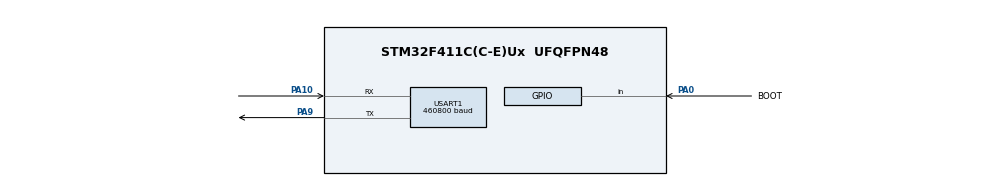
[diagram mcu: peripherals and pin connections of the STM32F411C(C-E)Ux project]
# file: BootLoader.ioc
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Dma.Request0=USART1_RX
Dma.USART1_RX.0.Direction=DMA_PERIPH_TO_MEMORY
Dma.USART1_RX.0.FIFOMode=DMA_FIFOMODE_DISABLE
Dma.USART1_RX.0.Instance=DMA2_Stream2
Dma.USART1_RX.0.MemDataAlignment=DMA_MDATAALIGN_BYTE
Dma.USART1_RX.0.MemInc=DMA_MINC_ENABLE
Dma.USART1_RX.0.Mode=DMA_CIRCULAR
Dma.USART1_RX.0.PeriphDataAlignment=DMA_PDATAALIGN_BYTE
Dma.USART1_RX.0.PeriphInc=DMA_PINC_DISABLE
Dma.USART1_RX.0.Priority=DMA_PRIORITY_HIGH
Mcu.Family=STM32F4
Mcu.Name=STM32F411C(C-E)Ux
Mcu.Package=UFQFPN48
NVIC.DMA2_Stream2_IRQn=true\:2\:0\:true\:false\:true\:false\:true\:true
NVIC.PriorityGroup=NVIC_PRIORITYGROUP_4
NVIC.USART1_IRQn=true\:1\:0\:true\:false\:true\:true\:true\:true
PA0-WKUP.GPIO_Label=BOOT
PA0-WKUP.GPIO_PuPd=GPIO_PULLUP
PA0-WKUP.Signal=GPIO_Input
PA10.Mode=Asynchronous
PA10.Signal=USART1_RX
PA13.Mode=Serial_Wire
PA13.Signal=SYS_JTMS-SWDIO
PA14.Mode=Serial_Wire
PA14.Signal=SYS_JTCK-SWCLK
PA9.Mode=Asynchronous
PA9.Signal=USART1_TX
PH0\ -\ OSC_IN.Mode=HSE-External-Oscillator
PH0\ -\ OSC_IN.Signal=RCC_OSC_IN
PH1\ -\ OSC_OUT.Mode=HSE-External-Oscillator
PH1\ -\ OSC_OUT.Signal=RCC_OSC_OUT
ProjectManager.HeapSize=0x200
ProjectManager.StackSize=0x400
ProjectManager.TargetToolchain=CMake
RCC.48MHZClocksFreq_Value=50000000
RCC.AHBFreq_Value=100000000
RCC.APB1CLKDivider=RCC_HCLK_DIV2
RCC.APB1Freq_Value=50000000
RCC.APB1TimFreq_Value=100000000
RCC.APB2Freq_Value=100000000
RCC.APB2TimFreq_Value=100000000
RCC.CortexFreq_Value=100000000
RCC.HCLKFreq_Value=100000000
RCC.HSE_VALUE=25000000
RCC.HSI_VALUE=16000000
RCC.LSE_VALUE=32768
RCC.PLLM=12
RCC.PLLN=96
RCC.PLLSourceVirtual=RCC_PLLSOURCE_HSE
RCC.SYSCLKFreq_VALUE=100000000
RCC.SYSCLKSource=RCC_SYSCLKSOURCE_PLLCLK
RCC.VCOOutputFreq_Value=200000000
USART1.BaudRate=460800
USART1.VirtualMode=VM_ASYNC
board=custom

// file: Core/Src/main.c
/* USER CODE BEGIN Header */
/**
  ******************************************************************************
  * @file           : main.c
  * @brief          : Main program body
  ******************************************************************************
  * @attention
  *
  * Copyright (c) 2026 STMicroelectronics.
  * All rights reserved.
  *
  * This software is licensed under terms that can be found in the LICENSE file
  * in the root directory of this software component.
  * If no LICENSE file comes with this software, it is provided AS-IS.
  *
  ******************************************************************************
  */
/* USER CODE END Header */
#include "main.h"
#include "dma.h"
#include "usart.h"
#include "gpio.h"

/* USER CODE BEGIN Includes */
#include <stdio.h>
#include "configBootloader.h"
#include "bootloader.h"
#include "uart_dma_ring.h"
#include "ymodem.h"
#include "flasher.h"
#include "ota.h"
#include "ota_download.h"
#include "bootloader_menu.h"
#include "lora.h"
/* USER CODE END Includes */

/* USER CODE BEGIN PV */

YM_InfoBlock_t g_ym_ctx;
OTA_Context_t  g_ota_ctx;
LoRa_Callback_t g_lora_cb;

/* extern from Core/Src/stm32f4xx_it.c */
extern volatile uint32_t g_sys_tick;

/* USER CODE END PV */

void SystemClock_Config(void);
/* USER CODE BEGIN PFP */
void CloseAllPeripheral(void);
static void BootloaderInit(void);
static uint32_t GetTick(void);
static void LoRa_SetMD0(uint8_t level);
static uint8_t LoRa_ReadAUX(void);
/* USER CODE END PFP */

int main(void)
{

  /* MCU Configuration--------------------------------------------------------*/

  /* Reset of all peripherals, Initializes the Flash interface and the Systick. */
  LL_APB2_GRP1_EnableClock(LL_APB2_GRP1_PERIPH_SYSCFG);
  LL_APB1_GRP1_EnableClock(LL_APB1_GRP1_PERIPH_PWR);

  /* System interrupt init*/
  NVIC_SetPriorityGrouping(NVIC_PRIORITYGROUP_4);

  /* Configure the system clock */
  SystemClock_Config();

  /* USER CODE BEGIN SysInit */
  SysTick->CTRL |= SysTick_CTRL_TICKINT_Msk;
  /* USER CODE END SysInit */

  /* Initialize all configured peripherals */
  MX_GPIO_Init();
  MX_DMA_Init();
  MX_USART1_UART_Init();
  /* USER CODE BEGIN 2 */

  BootloaderInit();
  BootMenu_PrintBanner();

  OTA_Param_t param;

/*-----------------------------------------------*/
// 进入OTA下载的触发逻辑
  {
    uint32_t start_time = GetTick();
    for (;;)
    {
        BootMenu_Action_t action = BootMenu_Poll(GetTick() - start_time);

        if (action == BOOTMENU_ACTION_ENTER_OTA)
        {
            if (OtaDownload_Execute(&g_ym_ctx, &g_ota_ctx, &param) == OTADL_STATUS_OK)
            {
                goto Jump;
            }
            else
            {
                goto err;
            }
        }
        if (action == BOOTMENU_ACTION_ENTER_LORA_OTA)
        {
            bootLoRa_ExitATMode();   /* 确保 LoRa 在透传模式 */
            if (OtaDownload_Execute(&g_ym_ctx, &g_ota_ctx, &param) == OTADL_STATUS_OK)
            {
                goto Jump;
            }
            else
            {
                goto err;
            }
        }
        if (action == BOOTMENU_ACTION_JUMP_APP)
        {
            goto Check;
        }
        if (action == BOOTMENU_ACTION_ENTER_MENU)
        {
            goto InteractiveMenu;
        }
    }
  }
/*-----------------------------------------------*/

InteractiveMenu:
/*-----------------------------------------------*/
// InteractiveMenu: 交互菜单模式

  {
    BootMenu_Action_t action = BootMenu_Interactive();

    if (action == BOOTMENU_ACTION_JUMP_APP)
    {
        goto Check;
    }
    if (action == BOOTMENU_ACTION_ENTER_OTA)
    {
        if (OtaDownload_Execute(&g_ym_ctx, &g_ota_ctx, &param) == OTADL_STATUS_OK)
        {
            goto Jump;
        }
        else
        {
            goto err;
        }
    }
    if (action == BOOTMENU_ACTION_ENTER_LORA_OTA)
    {
        bootLoRa_ExitATMode();   /* 确保 LoRa 在透传模式 */
        if (OtaDownload_Execute(&g_ym_ctx, &g_ota_ctx, &param) == OTADL_STATUS_OK)
        {
            goto Jump;
        }
        else
        {
            goto err;
        }
    }
    goto err;
  }
/*-----------------------------------------------*/

Check:
/*-----------------------------------------------*/
// 开机校验：读取 OTA 参数，校验活跃分区 CRC

  {
    if (bootOTA_ReadParamOTA(&g_ota_ctx, &param) != 0)
    {
      goto err;
    }

    uint32_t active_addr = bootOTA_GetActivePartitionAddr(&param);

    if (param.magic_flag == configOTA_VALID_MAGIC &&
        CalcCRC16((uint8_t*)active_addr, param.app_size) == (uint16_t)param.app_crc)
    {
      goto Jump;
    }
  }
/*-----------------------------------------------*/

Jump:
/*-----------------------------------------------*/
// Jump: 跳转到活跃分区 App

  printf("Ahh~I'm dead...~_~\r\n");
  Bootloader_JumpToApp(bootOTA_GetActivePartitionAddr(&param));
/*-----------------------------------------------*/

err:
/*-----------------------------------------------*/
  for(;;);
/*-----------------------------------------------*/

  /* USER CODE END 2 */

  /* Infinite loop */
  while (1)
  {

  }
}

void SystemClock_Config(void)
{
  LL_FLASH_SetLatency(LL_FLASH_LATENCY_3);
  while(LL_FLASH_GetLatency()!= LL_FLASH_LATENCY_3)
  {
  }
  LL_PWR_SetRegulVoltageScaling(LL_PWR_REGU_VOLTAGE_SCALE1);
  LL_RCC_HSE_Enable();

   /* Wait till HSE is ready */
  while(LL_RCC_HSE_IsReady() != 1)
  {

  }
  LL_RCC_PLL_ConfigDomain_SYS(LL_RCC_PLLSOURCE_HSE, LL_RCC_PLLM_DIV_12, 96, LL_RCC_PLLP_DIV_2);
  LL_RCC_PLL_Enable();

   /* Wait till PLL is ready */
  while(LL_RCC_PLL_IsReady() != 1)
  {

  }
  while (LL_PWR_IsActiveFlag_VOS() == 0)
  {
  }
  LL_RCC_SetAHBPrescaler(LL_RCC_SYSCLK_DIV_1);
  LL_RCC_SetAPB1Prescaler(LL_RCC_APB1_DIV_2);
  LL_RCC_SetAPB2Prescaler(LL_RCC_APB2_DIV_1);
  LL_RCC_SetSysClkSource(LL_RCC_SYS_CLKSOURCE_PLL);

   /* Wait till System clock is ready */
  while(LL_RCC_GetSysClkSource() != LL_RCC_SYS_CLKSOURCE_STATUS_PLL)
  {

  }
  LL_Init1msTick(100000000);
  LL_SetSystemCoreClock(100000000);
  LL_RCC_SetTIMPrescaler(LL_RCC_TIM_PRESCALER_TWICE);
}

/* USER CODE BEGIN 4 */

/**
 * @brief 重写 GNU C 库的底层 write 函数
 *
 * @param file 文件描述符 (1 代表标准输出 stdout)
 * @param ptr 要发送的字符数组指针
 * @param len 要发送的长度
 */
int _write(int file, char *ptr, int len)
{
    for (int i = 0; i < len; i++)
    {
        while (!LL_USART_IsActiveFlag_TXE(USART1));
        LL_USART_TransmitData8(USART1, ptr[i]);
    }
    return len;
}

void CloseAllPeripheral(void)
{

  LL_USART_DeInit(USART1);
  LL_DMA_DeInit(DMA2,LL_DMA_STREAM_2);
  LL_GPIO_DeInit(GPIOA);

}

static uint32_t GetTick(void)
{
  return g_sys_tick;
}

/**
 * @brief  MD0 引脚控制（占位，由用户按实际硬件补全）
 * @param  level  1 = 高电平（AT 模式）; 0 = 低电平（数据模式）
 */
static void LoRa_SetMD0(uint8_t level)
{

  if (level)
      LL_GPIO_SetOutputPin(LoRa_MD0_GPIO_Port, LoRa_MD0_Pin);
  else
      LL_GPIO_ResetOutputPin(LoRa_MD0_GPIO_Port, LoRa_MD0_Pin);

}

/**
 * @brief  AUX 引脚读取（占位，由用户按实际硬件补全）
 * @retval 1: 高电平（忙）; 0: 低电平（空闲）
 */
static uint8_t LoRa_ReadAUX(void)
{

    return ((LL_GPIO_ReadInputPort(LoRa_AUX_GPIO_Port) & BOOT_Pin)? 1 : 0);

}

static void BootloaderInit(void)
{
  g_ym_ctx.read_byte_cb = bootUART_ReadByte;
  g_ym_ctx.send_byte_cb = bootUART_SendByte;
  g_ym_ctx.get_tick_cb  = GetTick;

  g_ota_ctx.read_cb   = bootFlasher_ReadData;
  g_ota_ctx.write_cb  = bootFlasher_WriteByte;
  g_ota_ctx.erase_cb  = bootFlasher_EraseSectors;
  g_ota_ctx.unlock_cb = bootFlasher_Unlock;
  g_ota_ctx.lock_cb   = bootFlasher_Lock;

  // 初始化用于上位机传输文件的串口，而不是打印调试信息的串口
  bootUART_RegisterTransmitPort();

#if(configLORA)
  g_lora_cb.read_byte_cb = bootUART_ReadByte;
  g_lora_cb.send_byte_cb = bootUART_SendByte;
  g_lora_cb.get_tick_cb  = GetTick;
  g_lora_cb.set_md0_cb   = LoRa_SetMD0;
  g_lora_cb.read_aux_cb  = LoRa_ReadAUX;

  int8_t retry = 3 + 1; /* 重试次数为3 */
  int ret;
  do {
    if(retry <= 0)
    {
      for(;;);
    }
    ret = bootLoRa_Init(&g_lora_cb);
    retry--;
  }while (ret != 0);

#endif

}

/* USER CODE END 4 */

void Error_Handler(void)
{
  __disable_irq();
  while (1)
  {
  }
}
